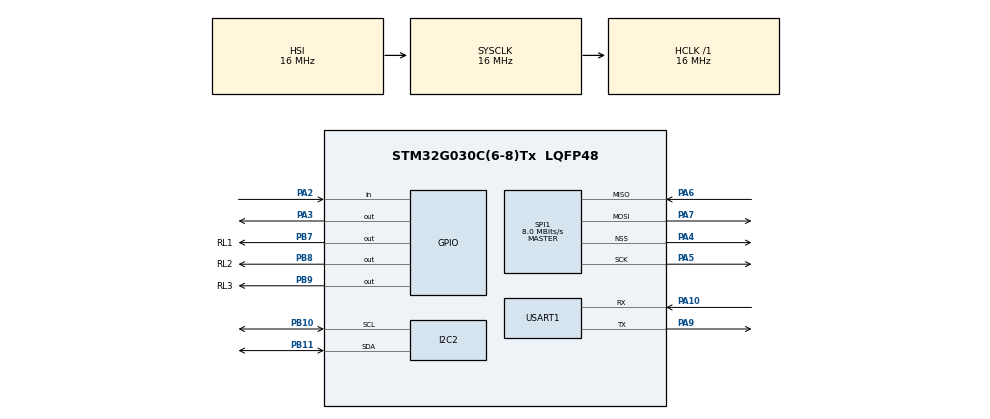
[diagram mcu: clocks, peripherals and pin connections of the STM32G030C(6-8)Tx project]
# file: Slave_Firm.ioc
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Mcu.Family=STM32G0
Mcu.Name=STM32G030C(6-8)Tx
Mcu.Package=LQFP48
PA10.Mode=Asynchronous
PA10.Signal=USART1_RX
PA13.Mode=Serial_Wire
PA13.Signal=SYS_SWDIO
PA14-BOOT0.Mode=Serial_Wire
PA14-BOOT0.Signal=SYS_SWCLK
PA2.Signal=GPIO_Input
PA3.Signal=GPIO_Output
PA4.Mode=NSS_Signal_Hard_Output
PA4.Signal=SPI1_NSS
PA5.Mode=Full_Duplex_Master
PA5.Signal=SPI1_SCK
PA6.Mode=Full_Duplex_Master
PA6.Signal=SPI1_MISO
PA7.Mode=Full_Duplex_Master
PA7.Signal=SPI1_MOSI
PA9.Mode=Asynchronous
PA9.Signal=USART1_TX
PB10.Mode=I2C
PB10.Signal=I2C2_SCL
PB11.Mode=I2C
PB11.Signal=I2C2_SDA
PB7.GPIO_Label=RL1
PB7.GPIO_Speed=GPIO_SPEED_FREQ_HIGH
PB7.Signal=GPIO_Output
PB8.GPIO_Label=RL2
PB8.GPIO_Speed=GPIO_SPEED_FREQ_HIGH
PB8.Signal=GPIO_Output
PB9.GPIO_Label=RL3
PB9.GPIO_Speed=GPIO_SPEED_FREQ_HIGH
PB9.Signal=GPIO_Output
PF0-OSC_IN\ (PF0).Mode=HSE-External-Oscillator
PF0-OSC_IN\ (PF0).Signal=RCC_OSC_IN
PF1-OSC_OUT\ (PF1).Mode=HSE-External-Oscillator
PF1-OSC_OUT\ (PF1).Signal=RCC_OSC_OUT
ProjectManager.HeapSize=0x200
ProjectManager.StackSize=0x400
ProjectManager.TargetToolchain=STM32CubeIDE
RCC.AHBFreq_Value=16000000
RCC.CortexFreq_Value=16000000
RCC.EXTERNAL_CLOCK_VALUE=12288000
RCC.HCLKFreq_Value=16000000
RCC.HSE_VALUE=8000000
RCC.HSI_VALUE=16000000
RCC.LSE_VALUE=32768
RCC.SYSCLKFreq_VALUE=16000000
RCC.VCOOutputFreq_Value=128000000
SPI1.CalculateBaudRate=8.0 MBits/s
SPI1.Direction=SPI_DIRECTION_2LINES
SPI1.Mode=SPI_MODE_MASTER
SPI1.VirtualNSS=VM_NSSHARD
SPI1.VirtualType=VM_MASTER
USART1.VirtualMode-Asynchronous=VM_ASYNC
board=custom

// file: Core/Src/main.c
/* USER CODE BEGIN Header */
/**
  ******************************************************************************
  * @file           : main.c
  * @brief          : Main program body
  ******************************************************************************
  * @attention
  *
  * Copyright (c) 2022 STMicroelectronics.
  * All rights reserved.
  *
  * This software is licensed under terms that can be found in the LICENSE file
  * in the root directory of this software component.
  * If no LICENSE file comes with this software, it is provided AS-IS.
  *
  ******************************************************************************
  */
/* USER CODE END Header */
#include "main.h"
#include "i2c.h"
#include "spi.h"
#include "usart.h"
#include "gpio.h"

/* USER CODE BEGIN Includes */
#include "aht10.h"
/* USER CODE END Includes */

void SystemClock_Config(void);

/* USER CODE BEGIN 0 */
void switch_relay(GPIO_PinState PinState)
{
	HAL_GPIO_WritePin(GPIOB, RL1_Pin, PinState);
	HAL_Delay(1000);
	HAL_GPIO_WritePin(GPIOB, RL2_Pin, PinState);
	HAL_Delay(1000);
	HAL_GPIO_WritePin(GPIOB, RL3_Pin, PinState);
	HAL_Delay(1000);
}
/* USER CODE END 0 */

int main(void)
{
  /* USER CODE BEGIN 1 */
  char temp[10] = {0};
  char hum[10] = {0};
  /* USER CODE END 1 */

  /* MCU Configuration--------------------------------------------------------*/

  /* Reset of all peripherals, Initializes the Flash interface and the Systick. */
  HAL_Init();

  /* Configure the system clock */
  SystemClock_Config();

  /* Initialize all configured peripherals */
  MX_GPIO_Init();
  MX_I2C2_Init();
  MX_SPI1_Init();
  MX_USART1_UART_Init();
  /* USER CODE BEGIN 2 */
//  switch_relay(GPIO_PIN_SET);
  /* USER CODE END 2 */

  /* Infinite loop */
  while (1)
  {

    /* USER CODE BEGIN 3 */
	HAL_GPIO_WritePin(GPIOB, RL1_Pin, GPIO_PIN_SET);
	HAL_Delay(1000);
	HAL_GPIO_WritePin(GPIOB, RL1_Pin, GPIO_PIN_RESET);
	HAL_Delay(1000);
  }
  /* USER CODE END 3 */
}

void SystemClock_Config(void)
{
  RCC_OscInitTypeDef RCC_OscInitStruct = {0};
  RCC_ClkInitTypeDef RCC_ClkInitStruct = {0};

  /** Configure the main internal regulator output voltage
  */
  HAL_PWREx_ControlVoltageScaling(PWR_REGULATOR_VOLTAGE_SCALE1);

  /** Initializes the RCC Oscillators according to the specified parameters
  * in the RCC_OscInitTypeDef structure.
  */
  RCC_OscInitStruct.OscillatorType = RCC_OSCILLATORTYPE_HSI;
  RCC_OscInitStruct.HSIState = RCC_HSI_ON;
  RCC_OscInitStruct.HSIDiv = RCC_HSI_DIV1;
  RCC_OscInitStruct.HSICalibrationValue = RCC_HSICALIBRATION_DEFAULT;
  RCC_OscInitStruct.PLL.PLLState = RCC_PLL_NONE;
  if (HAL_RCC_OscConfig(&RCC_OscInitStruct) != HAL_OK)
  {
    Error_Handler();
  }

  /** Initializes the CPU, AHB and APB buses clocks
  */
  RCC_ClkInitStruct.ClockType = RCC_CLOCKTYPE_HCLK|RCC_CLOCKTYPE_SYSCLK
                              |RCC_CLOCKTYPE_PCLK1;
  RCC_ClkInitStruct.SYSCLKSource = RCC_SYSCLKSOURCE_HSI;
  RCC_ClkInitStruct.AHBCLKDivider = RCC_SYSCLK_DIV1;
  RCC_ClkInitStruct.APB1CLKDivider = RCC_HCLK_DIV1;

  if (HAL_RCC_ClockConfig(&RCC_ClkInitStruct, FLASH_LATENCY_0) != HAL_OK)
  {
    Error_Handler();
  }
}

void Error_Handler(void)
{
  __disable_irq();
  while (1)
  {
  }
}
